AUTOSAR XML (schema 4.0)
package /ADAS_Components
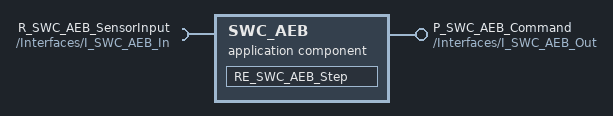
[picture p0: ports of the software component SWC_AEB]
  application sw component type SWC_AEB  # AUTOSAR Application SWC SWC_AEB for ADAS control
    provide port P_SWC_AEB_Command: provided-interface=/Interfaces/I_SWC_AEB_Out
    require port R_SWC_AEB_SensorInput: required-interface=/Interfaces/I_SWC_AEB_In
    behavior SWC_AEB_Behavior
      runnable RE_SWC_AEB_Step: symbol=SWC_AEB_Step
